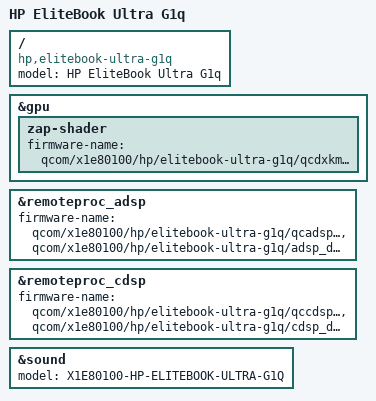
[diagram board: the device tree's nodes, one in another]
// SPDX-License-Identifier: BSD-3-Clause

/dts-v1/;

#include "x1e80100-hp-omnibook-x14.dts"

/ {
	model = "HP EliteBook Ultra G1q";
	compatible = "hp,elitebook-ultra-g1q", "qcom,x1e80100";
};

&gpu {
	zap-shader {
		firmware-name = "qcom/x1e80100/hp/elitebook-ultra-g1q/qcdxkmsuc8380.mbn";
	};
};

&remoteproc_adsp {
	firmware-name = "qcom/x1e80100/hp/elitebook-ultra-g1q/qcadsp8380.mbn",
			"qcom/x1e80100/hp/elitebook-ultra-g1q/adsp_dtbs.elf";
};

&remoteproc_cdsp {
	firmware-name = "qcom/x1e80100/hp/elitebook-ultra-g1q/qccdsp8380.mbn",
			"qcom/x1e80100/hp/elitebook-ultra-g1q/cdsp_dtbs.elf";
};

&sound {
	model = "X1E80100-HP-ELITEBOOK-ULTRA-G1Q";
};
